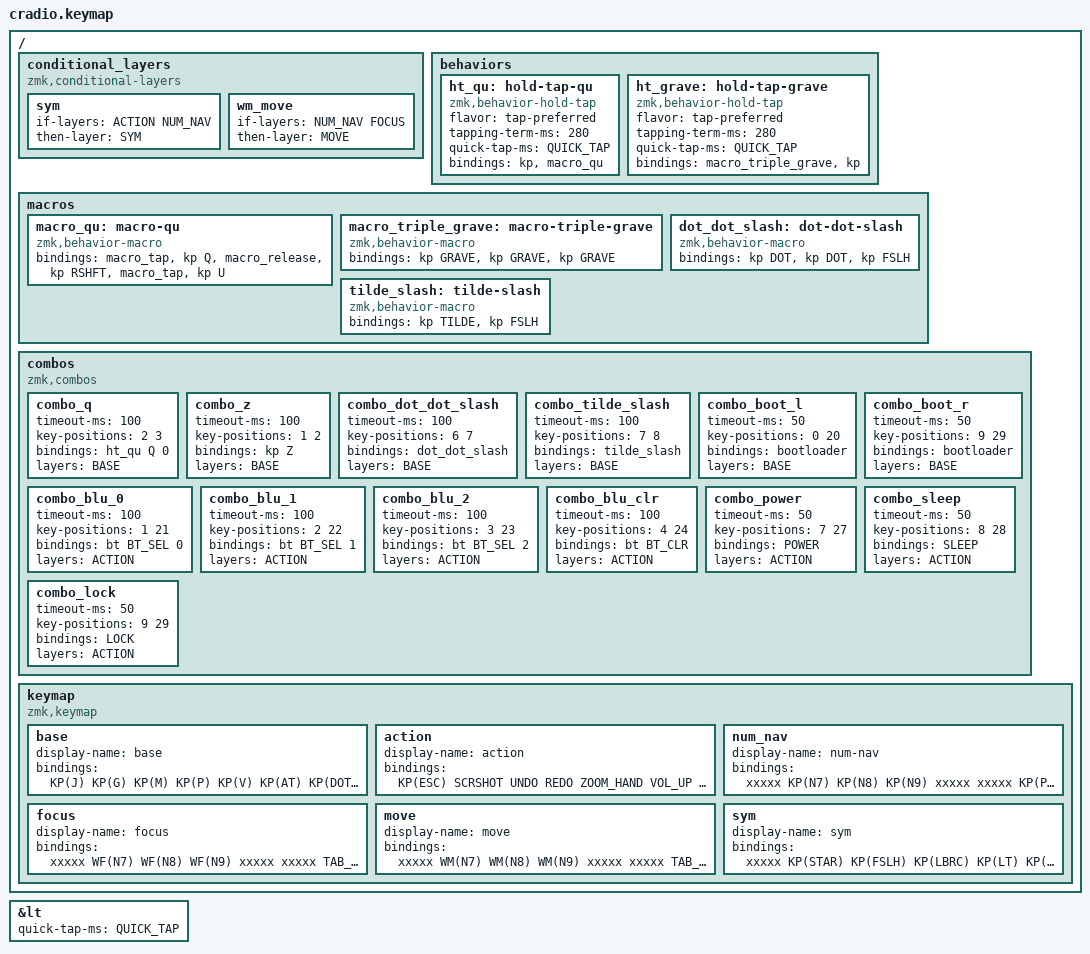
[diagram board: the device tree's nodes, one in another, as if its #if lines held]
#include <behaviors.dtsi>
#include <dt-bindings/zmk/keys.h>
#include <dt-bindings/zmk/bt.h>

#define BASE    0
#define ACTION  1
#define NUM_NAV 2
#define FOCUS   3
#define MOVE    4
#define SYM     5

// @draw-yq .layers.action[3][2].h = "sym"
// @draw-yq .layers."num-nav"[3][1].h = "sym"
// @draw-yq .layers.focus[3][2].h = "move"
// @draw-yq .layers."num-nav"[3][0].h = "move"

#undef CUT
#undef COPY
#undef UNDO

#define KP(k)       &kp k
#define SHFT_ENTER  &kp LS(ENTER)
#define TGRAVE      &ht_grave 0 GRAVE
#define HL(a,b,c,d) &hrl LCTRL a &hrl LALT b &hrl LGUI c &hrl LSHFT d
#define HR(a,b,c,d) &hrr RSHFT a &hrr RGUI b &hrr RALT c &hrr RCTRL d
#define L_A(t)      &lt 1 t
#define L_N(t)      &lt 2 t
#define L_F(t)      &lt 3 t
#define BT(c)       &bt BT_##c
#define BOOT        &bootloader
#define VOL_UP      &kp K_VOL_UP
#define VOL_DN      &kp K_VOL_DN
#define MUTE        &kp K_MUTE
#define _____       &trans
#define xxxxx       &none

#if defined(KEYMAP_OS_LINUX)
    #define SEL_ALL     &kp LC(A)
    #define CUT         &kp LC(X)
    #define COPY        &kp LC(C)
    #define PASTE       &kp LC(V)
    #define SPASTE      &kp LC(LS(V))
    #define UNDO        &kp LC(Z)
    #define REDO        &kp LC(LS(Z))
    #define LOCK        &kp LG(ESC)
    #define SLEEP       &kp LG(LS(S))
    #define POWER       &kp LG(LS(P))
    #define WF(k)       &kp LG(k)
    #define WM(k)       &kp LG(LS(k))
    #define SCRSHOT     &kp PSCRN
    #define ZOOM_HAND   &none
    #define ZOOM_VID    &none
    #define ZOOM_MUTE   &none
    #define TTY_OPEN    &kp LG(ENTER)
    #define TTY_COPY    &kp LC(LS(C))
    #define TTY_END     &kp LC(LS(END))
    #define TTY_PGUP    &kp LC(LS(COMMA))
    #define TTY_PGDN    &kp LC(LS(DOT))
    #define TTY_SCROLL  &kp LC(LS(H))
    #define CH_OPEN     &kp LG(LS(ENTER))
    #define CH_REOPEN   &kp LC(LS(T))
    #define CH_INCOG    &kp LC(LS(N))
    #define CH_REFRESH  &kp LC(LS(R))
    #define CH_ADDR     &kp LC(I)
    #define CH_FWD      &kp LA(RIGHT)
    #define CH_BACK     &kp LA(LEFT)
    #define WIN_CLOSE   &kp LG(LS(Q))
    #define TAB_NEW     &kp LC(T)
    #define TAB_CLOSE   &kp LC(F4)
    #define TAB_FL      &kp LC(PGUP)
    #define TAB_FR      &kp LC(PGDN)
    #define TAB_ML      &kp LC(LS(PGUP))
    #define TAB_MR      &kp LC(LS(PGDN))

#elif defined(KEYMAP_OS_MAC)
    #define SEL_ALL     &kp LG(A)
    #define CUT         &kp LG(X)
    #define COPY        &kp LG(C)
    #define PASTE       &kp LG(V)
    #define SPASTE      &kp LG(LS(V))
    #define UNDO        &kp LG(Z)
    #define REDO        &kp LG(LS(Z))
    #define LOCK        &kp LC(LG(Q))
    #define SLEEP       &kp LA(LG(K_PWR))
    #define POWER       &kp LC(LA(LG(K_PWR)))
    #define WF(k)       &kp LA(k)
    #define WM(k)       &kp LA(LS(k))
    #define SCRSHOT     &kp PSCRN
    #define ZOOM_HAND   &kp LC(LA(LS(H)))
    #define ZOOM_VID    &kp LC(LA(LS(V)))
    #define ZOOM_MUTE   &kp LC(LA(LS(A)))
    #define TTY_OPEN    &kp LC(LA(LS(T)))
    #define TTY_COPY    &kp LC(LS(C))
    #define TTY_END     &kp LC(LS(END))
    #define TTY_PGUP    &kp LC(LS(COMMA))
    #define TTY_PGDN    &kp LC(LS(DOT))
    #define TTY_SCROLL  &kp LC(LS(H))
    #define CH_OPEN     &kp LC(LA(LS(W)))
    #define CH_REOPEN   &kp LG(LS(T))
    #define CH_INCOG    &kp LG(LS(N))
    #define CH_REFRESH  &kp LG(LS(R))
    #define CH_ADDR     &kp LG(I)
    #define CH_FWD      &kp LG(RIGHT)
    #define CH_BACK     &kp LG(LEFT)
    #define WIN_CLOSE   &kp LA(LG(W))
    #define TAB_NEW     &kp LG(T)
    #define TAB_CLOSE   &kp LG(W)
    #define TAB_FL      &kp LG(LA(LEFT))
    #define TAB_FR      &kp LG(LA(RIGHT))
    #define TAB_ML      &kp LC(LS(PGUP))
    #define TAB_MR      &kp LC(LS(PGDN))

#else
    #error("KEYMAP_OS_LINUX or KEYMAP_OS_MAC not set")
#endif

#define QUICK_TAP   175

#define KEYS_L      0 1 2 3 4 10 11 12 13 14 20 21 22 23 24
#define KEYS_R      5 6 7 8 9 15 16 17 18 19 25 26 27 28 29
#define KEYS_T      30 31 32 33

#define MAKE_HRM(NAME, TRIGGER_POS) \
        NAME: NAME { \
            compatible = "zmk,behavior-hold-tap"; \
            #binding-cells = <2>; \
            flavor = "balanced"; \
            tapping-term-ms = <280>; \
            quick-tap-ms = <QUICK_TAP>; \
            require-prior-idle-ms = <150>; \
            bindings = <&kp>, <&kp>; \
            hold-trigger-key-positions = <TRIGGER_POS>; \
            hold-trigger-on-release; \
        };

&lt {
    quick-tap-ms = <QUICK_TAP>;
};

/ {
    conditional_layers {
        compatible = "zmk,conditional-layers";
        sym {
            if-layers = <ACTION NUM_NAV>;
            then-layer = <SYM>;
        };
        wm_move {
            if-layers = <NUM_NAV FOCUS>;
            then-layer = <MOVE>;
        };
    };

    behaviors {
        MAKE_HRM(hrl, KEYS_R KEYS_T)
        MAKE_HRM(hrr, KEYS_L KEYS_T)
        ht_qu: hold-tap-qu {
            compatible = "zmk,behavior-hold-tap";
            #binding-cells = <2>;
            flavor = "tap-preferred";
            tapping-term-ms = <280>;
            quick-tap-ms = <QUICK_TAP>;
            bindings = <&kp>, <&macro_qu>;
        };
        ht_grave: hold-tap-grave {
            compatible = "zmk,behavior-hold-tap";
            #binding-cells = <2>;
            flavor = "tap-preferred";
            tapping-term-ms = <280>;
            quick-tap-ms = <QUICK_TAP>;
            bindings = <&macro_triple_grave>, <&kp>;
        };
    };

    macros {
        macro_qu: macro-qu {
            compatible = "zmk,behavior-macro";
            #binding-cells = <0>;
            bindings
                = <&macro_tap &kp Q>
                , <&macro_release &kp RSHFT>
                , <&macro_tap &kp U>
                ;
        };
        macro_triple_grave: macro-triple-grave {
            compatible = "zmk,behavior-macro";
            #binding-cells = <0>;
            bindings = <&kp GRAVE &kp GRAVE &kp GRAVE>;
        };
        dot_dot_slash: dot-dot-slash {
            compatible = "zmk,behavior-macro";
            #binding-cells = <0>;
            bindings = <&kp DOT &kp DOT &kp FSLH>;
        };
        tilde_slash: tilde-slash {
            compatible = "zmk,behavior-macro";
            #binding-cells = <0>;
            bindings = <&kp TILDE &kp FSLH>;
        };
    };

    combos {
        compatible = "zmk,combos";
        combo_q {
            timeout-ms = <100>;
            key-positions = <2 3>;
            bindings = <&ht_qu Q 0>;
            layers = <BASE>;
        };
        combo_z {
            timeout-ms = <100>;
            key-positions = <1 2>;
            bindings = <&kp Z>;
            layers = <BASE>;
        };
        combo_dot_dot_slash {
            timeout-ms = <100>;
            key-positions = <6 7>;
            bindings = <&dot_dot_slash>;
            layers = <BASE>;
        };
        combo_tilde_slash {
            timeout-ms = <100>;
            key-positions = <7 8>;
            bindings = <&tilde_slash>;
            layers = <BASE>;
        };
        combo_boot_l {
            timeout-ms = <50>;
            key-positions = <0 20>;
            bindings = <&bootloader>;
            layers = <BASE>;
        };
        combo_boot_r {
            timeout-ms = <50>;
            key-positions = <9 29>;
            bindings = <&bootloader>;
            layers = <BASE>;
        };
        combo_blu_0 {
            timeout-ms = <100>;
            key-positions = <1 21>;
            bindings = <&bt BT_SEL 0>;
            layers = <ACTION>;
        };
        combo_blu_1 {
            timeout-ms = <100>;
            key-positions = <2 22>;
            bindings = <&bt BT_SEL 1>;
            layers = <ACTION>;
        };
        combo_blu_2 {
            timeout-ms = <100>;
            key-positions = <3 23>;
            bindings = <&bt BT_SEL 2>;
            layers = <ACTION>;
        };
        combo_blu_clr {
            timeout-ms = <100>;
            key-positions = <4 24>;
            bindings = <&bt BT_CLR>;
            layers = <ACTION>;
        };
        combo_power {
            timeout-ms = <50>;
            key-positions = <7 27>;
            bindings = <POWER>;
            layers = <ACTION>;
        };
        combo_sleep {
            timeout-ms = <50>;
            key-positions = <8 28>;
            bindings = <SLEEP>;
            layers = <ACTION>;
        };
        combo_lock {
            timeout-ms = <50>;
            key-positions = <9 29>;
            bindings = <LOCK>;
            layers = <ACTION>;
        };
    };

    // TODO:
    // international
    // linux test
    // wm resize
    // wm preset tile
    keymap {
        compatible = "zmk,keymap";

        base {
            display-name = "base";
            bindings = <
                KP(J)       KP(G)       KP(M)       KP(P)       KP(V)           KP(AT)      KP(DOT)     KP(FSLH)    KP(QMARK)      TGRAVE
                HL(R,          S,          N,          D)       KP(B)           KP(COMMA)   HR(A,          E,          I,          H)
                KP(X)       KP(F)       KP(L)       KP(C)       KP(W)           KP(MINUS)   KP(U)       KP(O)       KP(Y)       KP(K)
                                                    L_F(TAB)    L_A(T)          L_N(SPACE)  KP(ENTER)
            >;
        };

        action {
            display-name = "action";
            bindings = <
                KP(ESC)     SCRSHOT     UNDO        REDO        ZOOM_HAND       VOL_UP      TTY_OPEN    CH_OPEN     CH_REOPEN   WIN_CLOSE
                SEL_ALL     CUT         COPY        PASTE       ZOOM_VID        VOL_DN      TAB_NEW     CH_BACK     CH_FWD      CH_ADDR
                KP(INS)     xxxxx       TTY_COPY    SPASTE      ZOOM_MUTE       MUTE        KP(DEL)     CH_REFRESH  CH_INCOG    TAB_CLOSE
                                                    _____       _____           _____       KP(BSPC)
            >;
        };

        num_nav {
            display-name = "num-nav";
            bindings = <
                xxxxx       KP(N7)      KP(N8)      KP(N9)      xxxxx           xxxxx       KP(PG_UP)   KP(UP)      TTY_PGUP    xxxxx
                KP(DOT)     KP(N4)      KP(N5)      KP(N6)      xxxxx           KP(HOME)    KP(LEFT)    KP(DOWN)    KP(RIGHT)   KP(END)
                xxxxx       KP(N1)      KP(N2)      KP(N3)      xxxxx           xxxxx       KP(PG_DN)   TTY_SCROLL  TTY_PGDN    TTY_END
                                                    L_F(N0)     _____           _____       xxxxx
            >;
        };

        focus {
            display-name = "focus";
            bindings = <
                xxxxx       WF(N7)      WF(N8)      WF(N9)      xxxxx           xxxxx       TAB_FL      WF(UP)      TAB_FR      xxxxx
                xxxxx       WF(N4)      WF(N5)      WF(N6)      xxxxx           xxxxx       WF(LEFT)    WF(DOWN)    WF(RIGHT)   xxxxx
                xxxxx       WF(N1)      WF(N2)      WF(N3)      xxxxx           xxxxx       xxxxx       xxxxx       xxxxx       xxxxx
                                                    _____       xxxxx           _____       SHFT_ENTER
            >;
        };

        move {
            display-name = "move";
            bindings = <
                xxxxx       WM(N7)      WM(N8)      WM(N9)      xxxxx           xxxxx       TAB_ML      WM(UP)      TAB_MR      xxxxx
                xxxxx       WM(N4)      WM(N5)      WM(N6)      xxxxx           xxxxx       WM(LEFT)    WM(DOWN)    WM(RIGHT)   xxxxx
                xxxxx       WM(N1)      WM(N2)      WM(N3)      xxxxx           xxxxx       xxxxx       xxxxx       xxxxx       xxxxx
                                                    _____       xxxxx           _____       xxxxx
            >;
        };

        sym {
            display-name = "sym";
            bindings = <
                xxxxx       KP(STAR)    KP(FSLH)    KP(LBRC)    KP(LT)          KP(GT)      KP(RBRC)    KP(PLUS)    KP(MINUS)   xxxxx
                HL(HASH,       DLLR,       DQT,        LPAR)    KP(LBKT)        KP(RBKT)    HR(RPAR,       SQT,        AMPS,    PIPE)
                xxxxx       KP(EXCL)    KP(BSLH)    KP(EQUAL)   KP(PRCNT)       KP(CARET)   KP(UNDER)   KP(SEMI)    KP(COLON)   xxxxx
                                                    xxxxx       _____           _____       xxxxx
            >;
        };
    };
};
